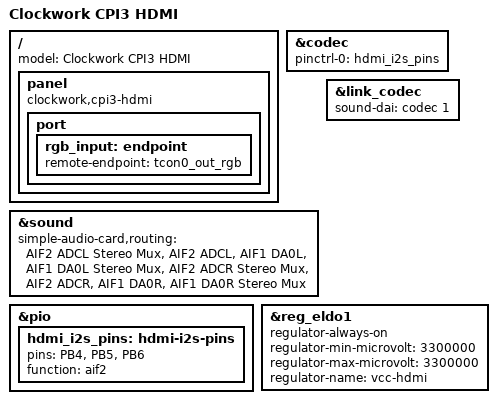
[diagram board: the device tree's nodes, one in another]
/*
 * Copyright (c) 2018 Clockwork
 *
 * This file is dual-licensed: you can use it either under the terms
 * of the GPL or the X11 license, at your option. Note that this dual
 * licensing only applies to this file, and not this project as a
 * whole.
 *
 *  a) This file is free software; you can redistribute it and/or
 *     modify it under the terms of the GNU General Public License as
 *     published by the Free Software Foundation; either version 2 of the
 *     License, or (at your option) any later version.
 *
 *     This file is distributed in the hope that it will be useful,
 *     but WITHOUT ANY WARRANTY; without even the implied warranty of
 *     MERCHANTABILITY or FITNESS FOR A PARTICULAR PURPOSE.  See the
 *     GNU General Public License for more details.
 *
 * Or, alternatively,
 *
 *  b) Permission is hereby granted, free of charge, to any person
 *     obtaining a copy of this software and associated documentation
 *     files (the "Software"), to deal in the Software without
 *     restriction, including without limitation the rights to use,
 *     copy, modify, merge, publish, distribute, sublicense, and/or
 *     sell copies of the Software, and to permit persons to whom the
 *     Software is furnished to do so, subject to the following
 *     conditions:
 *
 *     The above copyright notice and this permission notice shall be
 *     included in all copies or substantial portions of the Software.
 *
 *     THE SOFTWARE IS PROVIDED "AS IS", WITHOUT WARRANTY OF ANY KIND,
 *     EXPRESS OR IMPLIED, INCLUDING BUT NOT LIMITED TO THE WARRANTIES
 *     OF MERCHANTABILITY, FITNESS FOR A PARTICULAR PURPOSE AND
 *     NONINFRINGEMENT. IN NO EVENT SHALL THE AUTHORS OR COPYRIGHT
 *     HOLDERS BE LIABLE FOR ANY CLAIM, DAMAGES OR OTHER LIABILITY,
 *     WHETHER IN AN ACTION OF CONTRACT, TORT OR OTHERWISE, ARISING
 *     FROM, OUT OF OR IN CONNECTION WITH THE SOFTWARE OR THE USE OR
 *     OTHER DEALINGS IN THE SOFTWARE.
 */

/dts-v1/;
#include "sun8i-r16-clockworkpi-cpi3.dtsi"

/ {
	model = "Clockwork CPI3 HDMI";

	panel {
		compatible = "clockwork,cpi3-hdmi";

		port {
			rgb_input: endpoint {
				remote-endpoint = <&tcon0_out_rgb>;
			};
		};
	};
};

&codec {
	pinctrl-names = "default";
	pinctrl-0 = <&hdmi_i2s_pins>;
};

&sound {
	simple-audio-card,routing =
		"AIF2 ADCL Stereo Mux", "AIF2 ADCL",
		"AIF1 DA0L", "AIF1 DA0L Stereo Mux",
		"AIF2 ADCR Stereo Mux", "AIF2 ADCR",
		"AIF1 DA0R", "AIF1 DA0R Stereo Mux";
};

&link_codec {
	sound-dai = <&codec 1>;
};

&pio {
	hdmi_i2s_pins: hdmi-i2s-pins {
		pins = "PB4", "PB5", "PB6";
		function = "aif2";
	};
};

&reg_eldo1 {
	regulator-always-on;
	regulator-min-microvolt = <3300000>;
	regulator-max-microvolt = <3300000>;
	regulator-name = "vcc-hdmi";
};
